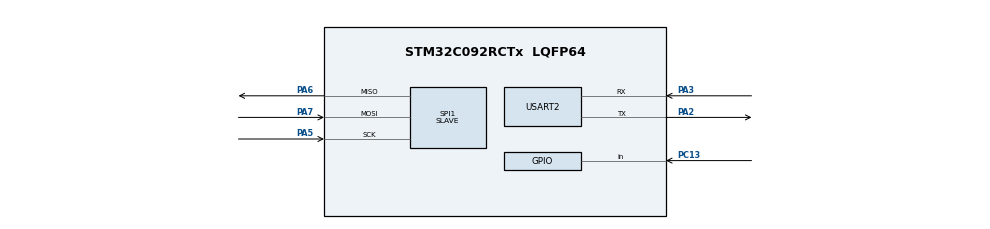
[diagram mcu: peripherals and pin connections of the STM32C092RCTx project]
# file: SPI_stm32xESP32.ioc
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Mcu.Family=STM32C0
Mcu.Name=STM32C092RCTx
Mcu.Package=LQFP64
PA2.Mode=Asynchronous
PA2.Signal=USART2_TX
PA3.Mode=Asynchronous
PA3.Signal=USART2_RX
PA5.Mode=Full_Duplex_Slave
PA5.Signal=SPI1_SCK
PA6.Mode=Full_Duplex_Slave
PA6.Signal=SPI1_MISO
PA7.Mode=Full_Duplex_Slave
PA7.Signal=SPI1_MOSI
PC13.Signal=GPIO_Input
PD0.Signal=FDCAN1_RX
PD1.Signal=FDCAN1_TX
PF0-OSC_IN(PF0).Mode=HSE-External-Oscillator
PF0-OSC_IN(PF0).Signal=RCC_OSC_IN
PF1-OSC_OUT(PF1).Mode=HSE-External-Oscillator
PF1-OSC_OUT(PF1).Signal=RCC_OSC_OUT
ProjectManager.HeapSize=0x200
ProjectManager.StackSize=0x400
ProjectManager.TargetToolchain=STM32CubeIDE
RCC.ADCFreq_Value=48000000
RCC.AHBFreq_Value=48000000
RCC.CortexFreq_Value=48000000
RCC.EXTERNAL_CLOCK_VALUE=12288000
RCC.EnbaleCSS=true
RCC.HCLKFreq_Value=48000000
RCC.HSE_VALUE=48000000
RCC.HSI_VALUE=48000000
RCC.LSE_VALUE=32768
RCC.SYSCLKFreq_VALUE=48000000
RCC.SYSCLKSource=RCC_SYSCLKSOURCE_HSE
SPI1.DataSize=SPI_DATASIZE_8BIT
SPI1.Direction=SPI_DIRECTION_2LINES
SPI1.Mode=SPI_MODE_SLAVE
SPI1.VirtualType=VM_SLAVE
USART2.VirtualMode-Asynchronous=VM_ASYNC
board=custom

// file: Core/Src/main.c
/* USER CODE BEGIN Header */
/**
  ******************************************************************************
  * @file           : main.c
  * @brief          : Main program body
  ******************************************************************************
  * @attention
  *
  * Copyright (c) 2026 STMicroelectronics.
  * All rights reserved.
  *
  * This software is licensed under terms that can be found in the LICENSE file
  * in the root directory of this software component.
  * If no LICENSE file comes with this software, it is provided AS-IS.
  *
  ******************************************************************************
  */
/* USER CODE END Header */
#include "main.h"

SPI_HandleTypeDef hspi1;

UART_HandleTypeDef huart2;

void SystemClock_Config(void);
static void MX_GPIO_Init(void);
static void MX_USART2_UART_Init(void);
static void MX_SPI1_Init(void);

/* USER CODE BEGIN 0 */

// User code for low-level USART transmission for printf() to terminal
int __io_putchar(char ch)
{
	HAL_UART_Transmit(&huart2, (uint8_t *)&ch, 1, 10);
	return ch;
}
/* USER CODE END 0 */

int main(void)
{

  /* USER CODE BEGIN 1 */
	char* msg = "\r\nLoop:\r\n";
	uint8_t tx_data = 'A';
	uint8_t rx_data = 'B';
  /* USER CODE END 1 */

  /* MCU Configuration--------------------------------------------------------*/

  /* Reset of all peripherals, Initializes the Flash interface and the Systick. */
  HAL_Init();

  /* Configure the system clock */
  SystemClock_Config();

  /* Initialize all configured peripherals */
  MX_GPIO_Init();
  MX_USART2_UART_Init();
  MX_SPI1_Init();
  /* USER CODE BEGIN 2 */
	// CS pin should default high
	HAL_GPIO_WritePin(GPIOA, GPIO_PIN_3, GPIO_PIN_RESET);
  /* USER CODE END 2 */

  /* Infinite loop */
  /* USER CODE BEGIN WHILE */
	while (1)
	{
	    HAL_UART_Transmit(&huart2, (uint8_t*)msg, strlen(msg), 500);

	    for (uint8_t i = 11; i <= 20; i++)
	    {
	        tx_data = i;
	        rx_data = 0;

	        // SPI transfer (send tx_data, receive into rx_data)
	        HAL_SPI_TransmitReceive(&hspi1, &tx_data, &rx_data, 1, HAL_MAX_DELAY);

	        // Print results over UART
	        char buffer[64];
	        snprintf(buffer, sizeof(buffer),
	                 "TX: %u | RX: %u\r\n",
	                 tx_data,
	                 rx_data);

	        HAL_UART_Transmit(&huart2, (uint8_t*)buffer, strlen(buffer), HAL_MAX_DELAY);
	    }

	    HAL_UART_Transmit(&huart2, (uint8_t*)"\r\n--- cycle done ---\r\n", 23, HAL_MAX_DELAY);

	    HAL_Delay(1000);
	}
  /* USER CODE END 3 */
}

void SystemClock_Config(void)
{
  RCC_OscInitTypeDef RCC_OscInitStruct = {0};
  RCC_ClkInitTypeDef RCC_ClkInitStruct = {0};

  __HAL_FLASH_SET_LATENCY(FLASH_LATENCY_1);

  /** Initializes the RCC Oscillators according to the specified parameters
  * in the RCC_OscInitTypeDef structure.
  */
  RCC_OscInitStruct.OscillatorType = RCC_OSCILLATORTYPE_HSE;
  RCC_OscInitStruct.HSEState = RCC_HSE_ON;
  if (HAL_RCC_OscConfig(&RCC_OscInitStruct) != HAL_OK)
  {
    Error_Handler();
  }

  /** Initializes the CPU, AHB and APB buses clocks
  */
  RCC_ClkInitStruct.ClockType = RCC_CLOCKTYPE_HCLK|RCC_CLOCKTYPE_SYSCLK
                              |RCC_CLOCKTYPE_PCLK1;
  RCC_ClkInitStruct.SYSCLKSource = RCC_SYSCLKSOURCE_HSE;
  RCC_ClkInitStruct.SYSCLKDivider = RCC_SYSCLK_DIV1;
  RCC_ClkInitStruct.AHBCLKDivider = RCC_HCLK_DIV1;
  RCC_ClkInitStruct.APB1CLKDivider = RCC_APB1_DIV1;

  if (HAL_RCC_ClockConfig(&RCC_ClkInitStruct, FLASH_LATENCY_1) != HAL_OK)
  {
    Error_Handler();
  }

  /** Enables the Clock Security System
  */
  HAL_RCC_EnableCSS();
}

static void MX_SPI1_Init(void)
{

  /* SPI1 parameter configuration*/
  hspi1.Instance = SPI1;
  hspi1.Init.Mode = SPI_MODE_SLAVE;
  hspi1.Init.Direction = SPI_DIRECTION_2LINES;
  hspi1.Init.DataSize = SPI_DATASIZE_8BIT;
  hspi1.Init.CLKPolarity = SPI_POLARITY_LOW;
  hspi1.Init.CLKPhase = SPI_PHASE_1EDGE;
  hspi1.Init.NSS = SPI_NSS_SOFT;
  hspi1.Init.FirstBit = SPI_FIRSTBIT_MSB;
  hspi1.Init.TIMode = SPI_TIMODE_DISABLE;
  hspi1.Init.CRCCalculation = SPI_CRCCALCULATION_DISABLE;
  hspi1.Init.CRCPolynomial = 7;
  hspi1.Init.CRCLength = SPI_CRC_LENGTH_DATASIZE;
  hspi1.Init.NSSPMode = SPI_NSS_PULSE_DISABLE;
  if (HAL_SPI_Init(&hspi1) != HAL_OK)
  {
    Error_Handler();
  }

}

static void MX_USART2_UART_Init(void)
{

  huart2.Instance = USART2;
  huart2.Init.BaudRate = 115200;
  huart2.Init.WordLength = UART_WORDLENGTH_8B;
  huart2.Init.StopBits = UART_STOPBITS_1;
  huart2.Init.Parity = UART_PARITY_NONE;
  huart2.Init.Mode = UART_MODE_TX_RX;
  huart2.Init.HwFlowCtl = UART_HWCONTROL_NONE;
  huart2.Init.OverSampling = UART_OVERSAMPLING_16;
  huart2.Init.OneBitSampling = UART_ONE_BIT_SAMPLE_DISABLE;
  huart2.Init.ClockPrescaler = UART_PRESCALER_DIV1;
  huart2.AdvancedInit.AdvFeatureInit = UART_ADVFEATURE_NO_INIT;
  if (HAL_UART_Init(&huart2) != HAL_OK)
  {
    Error_Handler();
  }

}

static void MX_GPIO_Init(void)
{
  GPIO_InitTypeDef GPIO_InitStruct = {0};

  /* GPIO Ports Clock Enable */
  __HAL_RCC_GPIOC_CLK_ENABLE();
  __HAL_RCC_GPIOF_CLK_ENABLE();
  __HAL_RCC_GPIOA_CLK_ENABLE();
  __HAL_RCC_GPIOD_CLK_ENABLE();

  /*Configure GPIO pin : PC13 */
  GPIO_InitStruct.Pin = GPIO_PIN_13;
  GPIO_InitStruct.Mode = GPIO_MODE_INPUT;
  GPIO_InitStruct.Pull = GPIO_NOPULL;
  HAL_GPIO_Init(GPIOC, &GPIO_InitStruct);

  /*Configure GPIO pins : PD0 PD1 */
  GPIO_InitStruct.Pin = GPIO_PIN_0|GPIO_PIN_1;
  GPIO_InitStruct.Mode = GPIO_MODE_AF_PP;
  GPIO_InitStruct.Pull = GPIO_NOPULL;
  GPIO_InitStruct.Speed = GPIO_SPEED_FREQ_LOW;
  GPIO_InitStruct.Alternate = GPIO_AF4_FDCAN1;
  HAL_GPIO_Init(GPIOD, &GPIO_InitStruct);

}

void Error_Handler(void)
{
  __disable_irq();
  while (1)
  {
  }
}
